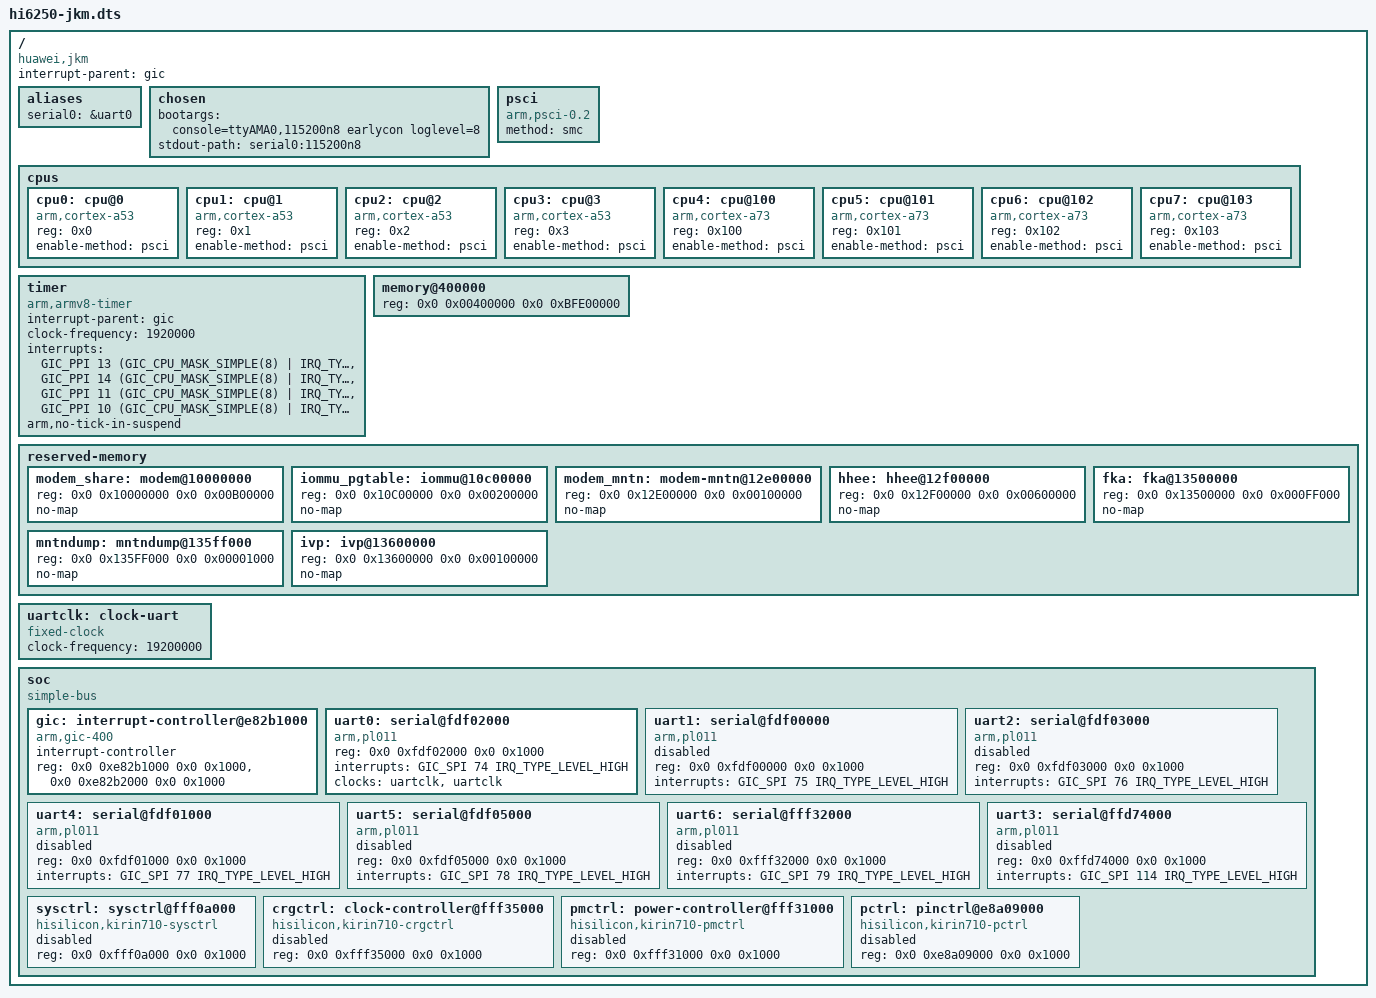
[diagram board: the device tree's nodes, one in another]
// SPDX-License-Identifier: GPL-2.0
/*
 * JKM (Huawei Enjoy 9 Plus) / Kirin 710 —— 主线 LTS 设备树骨架
 *
 * 这里的事实来自两处，逐项可追溯：
 *   - 厂商 4.9.148 开源源码 arch/arm64/boot/dts/auto-generate/config/kirin710/*.dtsi
 *   - 对厂商发布镜像 JKM_EMUI9.1_KernelSU.img 的离线逆向（见 docs/REVERSE_ENGINEERING.md）
 *
 * 现状：只描述 CPU / 内存 / 中断 / 定时器 / 串口，足以让 Image.gz 编译、
 * 让 dtb 通过 dtc 校验，并为串口调试提供早期输出。时钟、电源、MMC/UFS、
 * pinctrl、GPU、显示、触摸、modem 等主线驱动尚未移植，因此这份 dtb **不能让真机开机**。
 *
 * 标注 TODO(RE) 的节点是"闭源 / 厂商私有"部分，寄存器基址已从厂商 DTS
 * 提取，但主线 binding 与驱动需要后续逆向补齐，先保持 disabled。
 */

/dts-v1/;
#include <dt-bindings/interrupt-controller/irq.h>
#include <dt-bindings/interrupt-controller/arm-gic.h>

/ {
	compatible = "huawei,jkm", "hisilicon,kirin710";
	interrupt-parent = <&gic>;
	#address-cells = <2>;
	#size-cells = <2>;

	aliases {
		serial0 = &uart0;
	};

	chosen {
		bootargs = "console=ttyAMA0,115200n8 earlycon loglevel=8";
		stdout-path = "serial0:115200n8";
	};

	/* 厂商用 arm,psci + 显式 function ID；主线推荐 psci-0.2（SMC） */
	psci {
		compatible = "arm,psci-0.2", "arm,psci";
		method = "smc";
	};

	cpus {
		#address-cells = <1>;
		#size-cells = <0>;

		/* 4x Cortex-A53 little + 4x Cortex-A73 big */
		cpu0: cpu@0 {
			device_type = "cpu";
			compatible = "arm,cortex-a53", "arm,armv8";
			reg = <0x0>;
			enable-method = "psci";
		};
		cpu1: cpu@1 {
			device_type = "cpu";
			compatible = "arm,cortex-a53", "arm,armv8";
			reg = <0x1>;
			enable-method = "psci";
		};
		cpu2: cpu@2 {
			device_type = "cpu";
			compatible = "arm,cortex-a53", "arm,armv8";
			reg = <0x2>;
			enable-method = "psci";
		};
		cpu3: cpu@3 {
			device_type = "cpu";
			compatible = "arm,cortex-a53", "arm,armv8";
			reg = <0x3>;
			enable-method = "psci";
		};
		cpu4: cpu@100 {
			device_type = "cpu";
			compatible = "arm,cortex-a73", "arm,armv8";
			reg = <0x100>;
			enable-method = "psci";
		};
		cpu5: cpu@101 {
			device_type = "cpu";
			compatible = "arm,cortex-a73", "arm,armv8";
			reg = <0x101>;
			enable-method = "psci";
		};
		cpu6: cpu@102 {
			device_type = "cpu";
			compatible = "arm,cortex-a73", "arm,armv8";
			reg = <0x102>;
			enable-method = "psci";
		};
		cpu7: cpu@103 {
			device_type = "cpu";
			compatible = "arm,cortex-a73", "arm,armv8";
			reg = <0x103>;
			enable-method = "psci";
		};
	};

	/* 厂商: clock-frequency = <1920000>, PPI 13/14/11/10, flags 0xff08 */
	timer {
		compatible = "arm,armv8-timer";
		interrupt-parent = <&gic>;
		clock-frequency = <1920000>;
		interrupts = <GIC_PPI 13 (GIC_CPU_MASK_SIMPLE(8) | IRQ_TYPE_LEVEL_LOW)>,
			     <GIC_PPI 14 (GIC_CPU_MASK_SIMPLE(8) | IRQ_TYPE_LEVEL_LOW)>,
			     <GIC_PPI 11 (GIC_CPU_MASK_SIMPLE(8) | IRQ_TYPE_LEVEL_LOW)>,
			     <GIC_PPI 10 (GIC_CPU_MASK_SIMPLE(8) | IRQ_TYPE_LEVEL_LOW)>;
		arm,no-tick-in-suspend;
	};

	/* 厂商 kirin710_memory.dtsi: 起始 0x00400000, 长度 0xBFE00000 (~3 GiB) */
	memory@400000 {
		device_type = "memory";
		reg = <0x0 0x00400000 0x0 0xBFE00000>;
	};

	/* 厂商保留区：主线内核必须避开，否则会踩到 modem / ATF / 安全世界内存 */
	reserved-memory {
		#address-cells = <2>;
		#size-cells = <2>;
		ranges;

		modem_share: modem@10000000 {
			reg = <0x0 0x10000000 0x0 0x00B00000>;
			no-map;
		};
		iommu_pgtable: iommu@10c00000 {
			reg = <0x0 0x10C00000 0x0 0x00200000>;
			no-map;
		};
		modem_mntn: modem-mntn@12e00000 {
			reg = <0x0 0x12E00000 0x0 0x00100000>;
			no-map;
		};
		hhee: hhee@12f00000 {
			reg = <0x0 0x12F00000 0x0 0x00600000>;
			no-map;
		};
		fka: fka@13500000 {
			reg = <0x0 0x13500000 0x0 0x000FF000>;
			no-map;
		};
		mntndump: mntndump@135ff000 {
			reg = <0x0 0x135FF000 0x0 0x00001000>;
			no-map;
		};
		ivp: ivp@13600000 {
			reg = <0x0 0x13600000 0x0 0x00100000>;
			no-map;
		};
	};

	/* 占位：19.2 MHz 取自厂商 kirin710_clock.dtsi 的 clkin_sys，
	 * 但 UART 实际频率由 crgctrl 内 clk_mux_uart0 决定（mux @0xAC mask 0x4）。
	 * 完整时钟链与寄存器位定义见 docs/CLOCK_FACTS.md；
	 * 主线移植 clk-kirin710 后要把这里的 phandle 换成真实时钟节点。
	 */
	uartclk: clock-uart {
		compatible = "fixed-clock";
		#clock-cells = <0>;
		clock-frequency = <19200000>;
	};

	soc {
		compatible = "simple-bus";
		#address-cells = <2>;
		#size-cells = <2>;
		ranges;

		/* 厂商 kirin710_gic.dtsi: GICD 0xe82b1000 / GICC 0xe82b2000，GIC-400 (v2) */
		gic: interrupt-controller@e82b1000 {
			compatible = "arm,gic-400";
			#interrupt-cells = <3>;
			interrupt-controller;
			reg = <0x0 0xe82b1000 0x0 0x1000>,
			      <0x0 0xe82b2000 0x0 0x1000>;
			/* 厂商还有 PPI 9 maintenance IRQ (0xff04)，
			 * GIC 是根中断控制器，主线不写自引用的 interrupts 属性。 */
		};

		/* 厂商 serial0: uart@fdf02000, SPI 74, level high */
		uart0: serial@fdf02000 {
			compatible = "arm,pl011", "arm,primecell";
			reg = <0x0 0xfdf02000 0x0 0x1000>;
			interrupts = <GIC_SPI 74 IRQ_TYPE_LEVEL_HIGH>;
			clocks = <&uartclk &uartclk>;
			clock-names = "uartclk", "apb_pclk";
			status = "okay";
		};

		/* 其余 6 个 PL011：基址与 IRQ 来自 kirin710_uart.dtsi，先禁用 */
		uart1: serial@fdf00000 {
			compatible = "arm,pl011", "arm,primecell";
			reg = <0x0 0xfdf00000 0x0 0x1000>;
			interrupts = <GIC_SPI 75 IRQ_TYPE_LEVEL_HIGH>;
			status = "disabled";
		};
		uart2: serial@fdf03000 {
			compatible = "arm,pl011", "arm,primecell";
			reg = <0x0 0xfdf03000 0x0 0x1000>;
			interrupts = <GIC_SPI 76 IRQ_TYPE_LEVEL_HIGH>;
			status = "disabled";
		};
		uart4: serial@fdf01000 {
			compatible = "arm,pl011", "arm,primecell";
			reg = <0x0 0xfdf01000 0x0 0x1000>;
			interrupts = <GIC_SPI 77 IRQ_TYPE_LEVEL_HIGH>;
			status = "disabled";
		};
		uart5: serial@fdf05000 {
			compatible = "arm,pl011", "arm,primecell";
			reg = <0x0 0xfdf05000 0x0 0x1000>;
			interrupts = <GIC_SPI 78 IRQ_TYPE_LEVEL_HIGH>;
			status = "disabled";
		};
		uart6: serial@fff32000 {
			compatible = "arm,pl011", "arm,primecell";
			reg = <0x0 0xfff32000 0x0 0x1000>;
			interrupts = <GIC_SPI 79 IRQ_TYPE_LEVEL_HIGH>;
			status = "disabled";
		};
		uart3: serial@ffd74000 {
			compatible = "arm,pl011", "arm,primecell";
			reg = <0x0 0xffd74000 0x0 0x1000>;
			interrupts = <GIC_SPI 114 IRQ_TYPE_LEVEL_HIGH>;
			status = "disabled";
		};

		/* TODO(RE): 厂商私有控制器，基址已确认，主线 binding/驱动待逆向移植 */
		sysctrl: sysctrl@fff0a000 {
			compatible = "hisilicon,kirin710-sysctrl";
			reg = <0x0 0xfff0a000 0x0 0x1000>;
			status = "disabled";
		};
		crgctrl: clock-controller@fff35000 {
			compatible = "hisilicon,kirin710-crgctrl";
			reg = <0x0 0xfff35000 0x0 0x1000>;
			#clock-cells = <1>;
			status = "disabled";
		};
		pmctrl: power-controller@fff31000 {
			compatible = "hisilicon,kirin710-pmctrl";
			reg = <0x0 0xfff31000 0x0 0x1000>;
			status = "disabled";
		};
		pctrl: pinctrl@e8a09000 {
			compatible = "hisilicon,kirin710-pctrl";
			reg = <0x0 0xe8a09000 0x0 0x1000>;
			status = "disabled";
		};
	};
};
